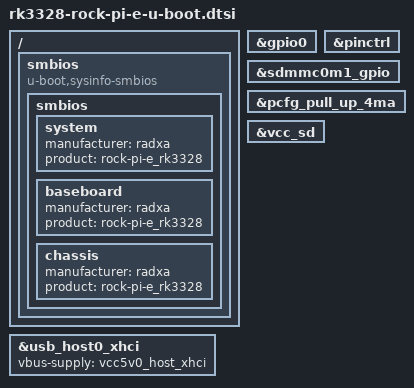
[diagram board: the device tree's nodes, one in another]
// SPDX-License-Identifier: GPL-2.0+
/*
 * (C) Copyright 2020 Radxa
 */

#include "rk3328-u-boot.dtsi"
#include "rk3328-sdram-ddr3-666.dtsi"

/ {
	smbios {
		compatible = "u-boot,sysinfo-smbios";

		smbios {
			system {
				manufacturer = "radxa";
				product = "rock-pi-e_rk3328";
			};

			baseboard {
				manufacturer = "radxa";
				product = "rock-pi-e_rk3328";
			};

			chassis {
				manufacturer = "radxa";
				product = "rock-pi-e_rk3328";
			};
		};
	};
};

&gpio0 {
	u-boot,dm-spl;
};

&pinctrl {
	u-boot,dm-spl;
};

&sdmmc0m1_gpio {
	u-boot,dm-spl;
};

&pcfg_pull_up_4ma {
	u-boot,dm-spl;
};

&usb_host0_xhci {
	vbus-supply = <&vcc5v0_host_xhci>;
	status = "okay";
};

/* Need this and all the pinctrl/gpio stuff above to set pinmux */
&vcc_sd {
	u-boot,dm-spl;
};
